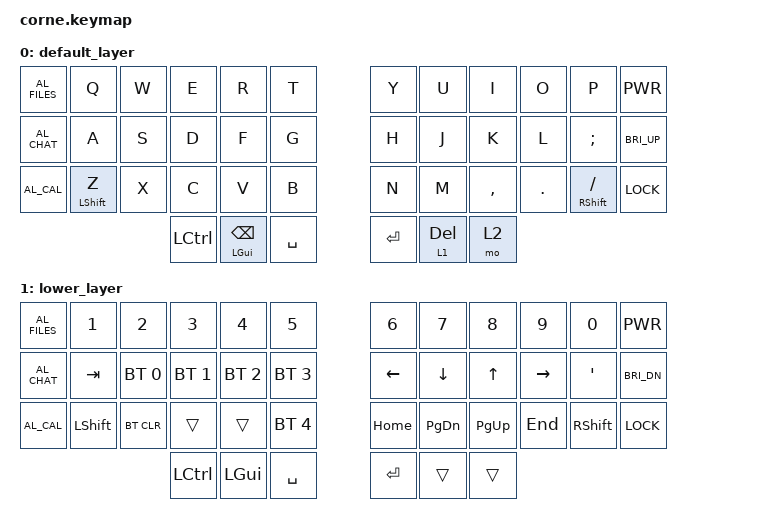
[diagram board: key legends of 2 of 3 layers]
/*
 * Copyright (c) 2020 The ZMK Contributors
 *
 * SPDX-License-Identifier: MIT
 */

#include <behaviors.dtsi>
#include <dt-bindings/zmk/keys.h>
#include <dt-bindings/zmk/bt.h>
#include <dt-bindings/zmk/outputs.h>

/ {
        keymap {
                compatible = "zmk,keymap";

                default_layer {
// -----------------------------------------------------------------------------------------
// | FILES |  Q       |  W  |  E  |  R  |  T  |   |  Y  |  U   |  I  |  O  |  P       | PWR   |
// | CHAT  |  A       |  S  |  D  |  F  |  G  |   |  H  |  J   |  K  |  L  |  ;       | BR_UP |
// | CAL   |  Lsft/Z  |  X  |  C  |  V  |  B  |   |  N  |  M   |  ,  |  .  |  Rsft//  | LOCK  |
//                    | CTL | GUI/BS | SPC |   | ENT | L1/Del  | L2 |
                        bindings = <
   &kp C_AL_FILES &kp Q &kp W &kp E &kp R &kp T        &kp Y &kp U  &kp I     &kp O   &kp P          &kp K_PWR
   &kp C_AL_CHAT  &kp A &kp S &kp D &kp F &kp G        &kp H &kp J  &kp K     &kp L   &kp SEMI       &kp C_BRI_UP
   &kp C_AL_CAL   &mt LSHFT Z &kp X &kp C &kp V &kp B  &kp N &kp M  &kp COMMA &kp DOT &mt RSHFT FSLH &kp K_LOCK
                  &kp LCTRL &mt LGUI BSPC &kp SPACE    &kp RET &lt 1 DEL &mo 2
                        >;
                };
                lower_layer {
// -----------------------------------------------------------------------------------------
// | FILES |  1  |  2  |  3  |  4  |  5  |   |  6  |  7  |  8  |  9  |  0  | PWR   |
// | CHAT  | TAB | BT1 | BT2 | BT3 | BT4 |   | LFT | DWN |  UP | RGT |  '  | BR_DN |
// | CAL   |LSHFT|BT_CL|     |     | BT5 |   | HOME| PGDN| PGUP| END | Rsft| LOCK  |
//                     | CTL | GUI | SPC |   | ENT |     | ALT |
                        bindings = <
   &kp C_AL_FILES &kp N1       &kp N2       &kp N3       &kp N4       &kp N5         &kp N6   &kp N7    &kp N8    &kp N9    &kp N0    &kp K_PWR
   &kp C_AL_CHAT  &kp TAB      &bt BT_SEL 0 &bt BT_SEL 1 &bt BT_SEL 2 &bt BT_SEL 3   &kp LEFT &kp DOWN  &kp UP    &kp RIGHT &kp SQT   &kp C_BRI_DN
   &kp C_AL_CAL   &kp LSHFT    &bt BT_CLR   &trans       &trans       &bt BT_SEL 4   &kp HOME &kp PG_DN &kp PG_UP &kp END   &kp RSHFT &kp K_LOCK
                  &kp LCTRL    &kp LGUI     &kp SPACE    &kp RET      &trans   &trans
                        >;
                };

                raise_layer {
// -----------------------------------------------------------------------------------------
// | FILES | ESC | F1  | F2  | F3  | F4  |   | USB | BLE |     |  =  |  -  | PWR   |
// | CHAT  | CTL | F5  | F6  | F7  | F8  |   |  [  |  ]  |     |  `  |  \  | BR_UP |
// | CAL   |LSHFT| F9  | F10 | F11 | F12 |   |     |     |     |     |RSHFT| LOCK  |
//                     | CTL | GUI | ALT |   | RST | ALT | L2  |
                        bindings = <
   &kp C_AL_FILES   &kp ESC &kp F1 &kp F2 &kp F3 &kp F4 &out OUT_USB &out OUT_BLE &none  &kp EQUAL &kp MINUS &kp K_PWR
   &kp C_AL_CHAT    &kp LCTRL &kp F5 &kp F6 &kp F7 &kp F8 &kp LBKT &kp RBKT &none &kp GRAVE &kp BSLH &kp C_BRI_UP
   &kp C_AL_CAL     &kp LSHFT &kp F9 &kp F10 &kp F11 &kp F12 &none &none &none &kp RSHFT &kp K_LOCK
                            &kp LCTRL &kp LGUI &kp LALT &sys_reset &kp RALT &trans
                        >;
                };
        };
};
